# MCXN947_cm33_core0 register map
Vendor: nxp.com; File version: 1.0
CPU: CM33 r2p0, little endian, MPU, FPU, VTOR, 3 interrupt priority bits
Registers are 32-bit, read-write, reset 0x0 unless marked. A register's access mark holds for its fields unless they carry their own. Offsets are from the block's base; [hi:lo] are bit positions; lines under a group give offsets from that group; {n}, {i} and the like mark numbered series; 'fields as' and 'values as' point back to an identical list.

## EVTG0 — EVTG
Base 0x400D2000
{0x0+0x10*i} EVTG_INST[{i}] (i=0..3) group
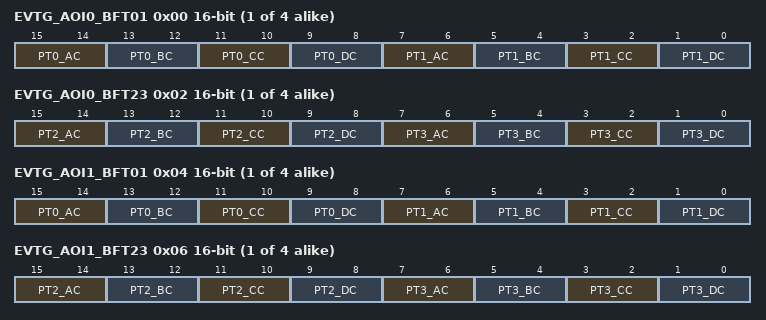
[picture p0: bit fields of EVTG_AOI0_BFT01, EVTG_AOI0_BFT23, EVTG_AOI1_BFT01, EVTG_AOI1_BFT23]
  0x00 EVTG_AOI0_BFT01 16-bit — AOI0 Boolean Function Term 0 and 1 Configuration
    [15:14] PT0_AC — Product Term 0, A Input Configuration
      0=Force the A input in this product term to a logical zero; 1=Pass the A input in this product term; 2=Complement the A input in this product term; 3=Force the A input in this product term to a logical one
    [13:12] PT0_BC — Product Term 0, B Input Configuration
      0=Force the B input in this product term to a logical zero; 1=Pass the B input in this product term; 2=Complement the B input in this product term; 3=Force the B input in this product term to a logical one
    [11:10] PT0_CC — Product Term 0, C Input Configuration
      0=CC0_0 (Force the C input in this product term to a logical zero); 1=CC0_1 (Pass the C input in this product term); 2=CC0_2 (Complement the C input in this product term); 3=CC0_3 (Force the C input in this product term to a logical one)
    [9:8] PT0_DC — Product Term 0, D Input Configuration
      0=DC_0 (Force the D input in this product term to a logical zero); 1=DC_1 (Pass the D input in this product term); 2=DC_2 (Complement the D input in this product term); 3=DC_3 (Force the D input in this product term to a logical one)
    [7:6] PT1_AC — Product Term 1, A Input Configuration
      0=AC_0 (Force the A input in this product term to a logical zero); 1=AC_1 (Pass the A input in this product term); 2=AC_2 (Complement the A input in this product term); 3=AC_3 (Force the A input in this product term to a logical one)
    [5:4] PT1_BC — Product Term 1, B Input Configuration
      0=BC_0 (Force the B input in this product term to a logical zero); 1=BC_1 (Pass the B input in this product term); 2=BC_2 (Complement the B input in this product term); 3=BC_3 (Force the B input in this product term to a logical one)
    [3:2] PT1_CC — Product Term 1, C Input Configuration
      0=CC_0 (Force the C input in this product term to a logical zero); 1=CC_1 (Pass the C input in this product term); 2=CC_2 (Complement the C input in this product term); 3=CC_3 (Force the C input in this product term to a logical one)
    [1:0] PT1_DC — Product Term 1, D Input Configuration
      0=Force the D input in this product term to a logical zero; 1=Pass the D input in this product term; 2=Complement the D input in this product term; 3=Force the D input in this product term to a logical one
  0x02 EVTG_AOI0_BFT23 16-bit — AOI0 Boolean Function Term 2 and 3 Configuration
    [15:14] PT2_AC — Product Term 2, A Input Configuration
      values as EVTG_INST[0].EVTG_AOI0_BFT01.PT0_AC
    [13:12] PT2_BC — Product Term 2, B Input Configuration
      values as EVTG_INST[0].EVTG_AOI0_BFT01.PT0_BC
    [11:10] PT2_CC — Product Term 2, C Input Configuration
      0=Force the C input in this product term to a logical zero; 1=Pass the C input in this product term; 2=Complement the C input in this product term; 3=Force the C input in this product term to a logical one
    [9:8] PT2_DC — Product Term 2, D Input Configuration
      values as EVTG_INST[0].EVTG_AOI0_BFT01.PT1_DC
    [7:6] PT3_AC — Product Term 3, A Input Configuration
      values as EVTG_INST[0].EVTG_AOI0_BFT01.PT0_AC
    [5:4] PT3_BC — Product Term 3, B Input Configuration
      values as EVTG_INST[0].EVTG_AOI0_BFT01.PT0_BC
    [3:2] PT3_CC — Product Term 3, C Input Configuration
      values as PT2_CC
    [1:0] PT3_DC — Product Term 3, D Input Configuration
      values as EVTG_INST[0].EVTG_AOI0_BFT01.PT1_DC
  0x04 EVTG_AOI1_BFT01 16-bit — AOI1 Boolean Function Term 0 and 1 Configuration
    [15:14] PT0_AC — Product Term 0, A Input Configuration
      values as EVTG_INST[0].EVTG_AOI0_BFT01.PT0_AC
    [13:12] PT0_BC — Product Term 0, B Input Configuration
      values as EVTG_INST[0].EVTG_AOI0_BFT01.PT0_BC
    [11:10] PT0_CC — Product Term 0, C Input Configuration
      values as EVTG_INST[0].EVTG_AOI0_BFT23.PT2_CC
    [9:8] PT0_DC — Product Term 0, D Input Configuration
      values as EVTG_INST[0].EVTG_AOI0_BFT01.PT1_DC
    [7:6] PT1_AC — Product Term 1, A Input Configuration
      values as EVTG_INST[0].EVTG_AOI0_BFT01.PT0_AC
    [5:4] PT1_BC — Product Term 1, B Input Configuration
      values as EVTG_INST[0].EVTG_AOI0_BFT01.PT0_BC
    [3:2] PT1_CC — Product Term 1, C Input Configuration
      values as EVTG_INST[0].EVTG_AOI0_BFT23.PT2_CC
    [1:0] PT1_DC — Product Term 1, D Input Configuration
      values as EVTG_INST[0].EVTG_AOI0_BFT01.PT1_DC
  0x06 EVTG_AOI1_BFT23 16-bit — AOI1 Boolean Function Term 2 and 3 Configuration
    fields as EVTG_INST[0].EVTG_AOI0_BFT23
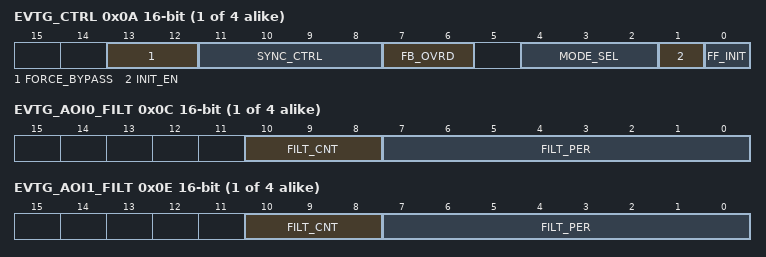
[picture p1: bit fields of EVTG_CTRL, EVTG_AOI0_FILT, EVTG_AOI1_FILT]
  0x0A EVTG_CTRL 16-bit — Control and Status
    [13:12] FORCE_BYPASS — Force Bypass Control
      0bx0=NFB0 (Will not force the bypass); 0bx1=F_FF_A (Whatever MODE_SEL is, will force bypass flip-flop and route the AOI_0(Filter_0) value directly to EVTG_OUTA)
    [11:8] SYNC_CTRL — Synchronize Control
      0bxxx0=A_NOTSYNC (EVTG input "An" will not be synced); 0bxxx1=A_SYNC (EVTG input "An" will be synced by two bus clk cycles)
    [7:6] FB_OVRD — EVTG Output Feedback Override Control
      0=An (Replace An); 1=Bn (Replace Bn); 2=Cn (Replace Cn); 3=Dn (Replace Dn)
    [4:2] MODE_SEL — Flip-Flop Mode Selection
      0=Bypass mode; 1=RS (RS Trigger mode); 2=TFF (T-FF mode); 3=DFF (D-FF mode); 4=JKFF (JK-FF mode); 5=LATCH (Latch mode)
    [1] INIT_EN — Flip-Flop Initial Output Enable Control
      0=PULSE (Write 0 does not generate enable pulse); 1=NO_PULSE (Write 1 generates enable pulse)
    [0] FF_INIT — Flip flop Initial Value Configuration
      0=FF0 (0); 1=FF1 (1)
  0x0C EVTG_AOI0_FILT 16-bit — AOI0 Output Filter
    [10:8] FILT_CNT — Output Filter Sample Count
    [7:0] FILT_PER — Output Filter Sample Period
  0x0E EVTG_AOI1_FILT 16-bit — AOI1 Output Filter
    fields as EVTG_INST[0].EVTG_AOI0_FILT
